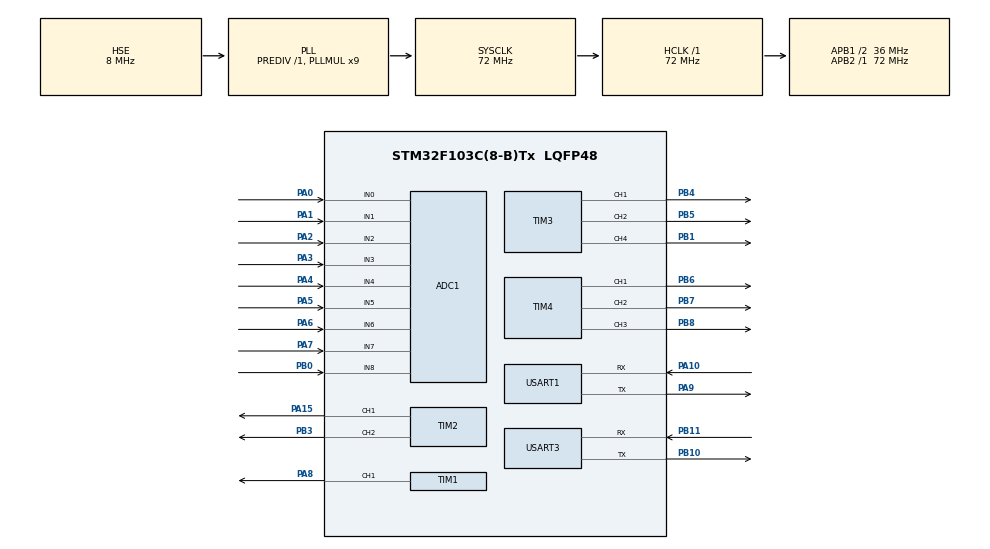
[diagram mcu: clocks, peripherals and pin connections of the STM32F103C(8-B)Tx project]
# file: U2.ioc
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ADC1.Channel-0\#ChannelRegularConversion=ADC_CHANNEL_0
ADC1.NbrOfConversionFlag=1
ADC1.Rank-0\#ChannelRegularConversion=1
ADC1.SamplingTime-0\#ChannelRegularConversion=ADC_SAMPLETIME_1CYCLE_5
ADC1.master=1
Mcu.Family=STM32F1
Mcu.Name=STM32F103C(8-B)Tx
Mcu.Package=LQFP48
NVIC.PriorityGroup=NVIC_PRIORITYGROUP_4
PA0-WKUP.Signal=ADCx_IN0
PA1.Signal=ADCx_IN1
PA10.Mode=Asynchronous
PA10.Signal=USART1_RX
PA13.Mode=Serial_Wire
PA13.Signal=SYS_JTMS-SWDIO
PA14.Mode=Serial_Wire
PA14.Signal=SYS_JTCK-SWCLK
PA15.Signal=S_TIM2_CH1_ETR
PA2.Signal=ADCx_IN2
PA3.Signal=ADCx_IN3
PA4.Signal=ADCx_IN4
PA5.Signal=ADCx_IN5
PA6.Signal=ADCx_IN6
PA7.Signal=ADCx_IN7
PA8.Signal=S_TIM1_CH1
PA9.Mode=Asynchronous
PA9.Signal=USART1_TX
PB0.Signal=ADCx_IN8
PB1.Signal=S_TIM3_CH4
PB10.Mode=Asynchronous
PB10.Signal=USART3_TX
PB11.Mode=Asynchronous
PB11.Signal=USART3_RX
PB3.Signal=S_TIM2_CH2
PB4.Signal=S_TIM3_CH1
PB5.Signal=S_TIM3_CH2
PB6.Signal=S_TIM4_CH1
PB7.Signal=S_TIM4_CH2
PB8.Signal=S_TIM4_CH3
PD0-OSC_IN.Mode=HSE-External-Oscillator
PD0-OSC_IN.Signal=RCC_OSC_IN
PD1-OSC_OUT.Mode=HSE-External-Oscillator
PD1-OSC_OUT.Signal=RCC_OSC_OUT
ProjectManager.HeapSize=0x200
ProjectManager.StackSize=0x400
ProjectManager.TargetToolchain=MDK-ARM V5
RCC.ADCPresc=RCC_ADCPCLK2_DIV6
RCC.AHBFreq_Value=72000000
RCC.APB1CLKDivider=RCC_HCLK_DIV2
RCC.APB1Freq_Value=36000000
RCC.APB1TimFreq_Value=72000000
RCC.APB2Freq_Value=72000000
RCC.APB2TimFreq_Value=72000000
RCC.HCLKFreq_Value=72000000
RCC.PLLMUL=RCC_PLL_MUL9
RCC.PLLSourceVirtual=RCC_PLLSOURCE_HSE
RCC.SYSCLKFreq_VALUE=72000000
RCC.SYSCLKSource=RCC_SYSCLKSOURCE_PLLCLK
RCC.USBFreq_Value=72000000
SH.ADCx_IN0.0=ADC1_IN0,IN0
SH.ADCx_IN1.0=ADC1_IN1,IN1
SH.ADCx_IN2.0=ADC1_IN2,IN2
SH.ADCx_IN3.0=ADC1_IN3,IN3
SH.ADCx_IN4.0=ADC1_IN4,IN4
SH.ADCx_IN5.0=ADC1_IN5,IN5
SH.ADCx_IN6.0=ADC1_IN6,IN6
SH.ADCx_IN7.0=ADC1_IN7,IN7
SH.ADCx_IN8.0=ADC1_IN8,IN8
SH.S_TIM1_CH1.0=TIM1_CH1,Output Compare1 CH1
SH.S_TIM2_CH1_ETR.0=TIM2_CH1,PWM Generation1 CH1
SH.S_TIM2_CH2.0=TIM2_CH2,PWM Generation2 CH2
SH.S_TIM3_CH1.0=TIM3_CH1,PWM Generation1 CH1
SH.S_TIM3_CH2.0=TIM3_CH2,PWM Generation2 CH2
SH.S_TIM3_CH4.0=TIM3_CH4,PWM Generation4 CH4
SH.S_TIM4_CH1.0=TIM4_CH1,PWM Generation1 CH1
SH.S_TIM4_CH2.0=TIM4_CH2,PWM Generation2 CH2
SH.S_TIM4_CH3.0=TIM4_CH3,PWM Generation3 CH3
TIM1.Channel-Output\ Compare1\ CH1=TIM_CHANNEL_1
TIM2.Channel-PWM\ Generation1\ CH1=TIM_CHANNEL_1
TIM2.Channel-PWM\ Generation2\ CH2=TIM_CHANNEL_2
TIM3.Channel-PWM\ Generation1\ CH1=TIM_CHANNEL_1
TIM3.Channel-PWM\ Generation2\ CH2=TIM_CHANNEL_2
TIM3.Channel-PWM\ Generation4\ CH4=TIM_CHANNEL_4
TIM4.Channel-PWM\ Generation1\ CH1=TIM_CHANNEL_1
TIM4.Channel-PWM\ Generation2\ CH2=TIM_CHANNEL_2
TIM4.Channel-PWM\ Generation3\ CH3=TIM_CHANNEL_3
USART1.VirtualMode=VM_ASYNC
USART3.VirtualMode=VM_ASYNC
board=custom

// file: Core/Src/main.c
/* USER CODE BEGIN Header */
/**
  ******************************************************************************
  * @file           : main.c
  * @brief          : Main program body
  ******************************************************************************
  * @attention
  *
  * Copyright (c) 2026 STMicroelectronics.
  * All rights reserved.
  *
  * This software is licensed under terms that can be found in the LICENSE file
  * in the root directory of this software component.
  * If no LICENSE file comes with this software, it is provided AS-IS.
  *
  ******************************************************************************
  */
/* USER CODE END Header */
#include "main.h"
#include "adc.h"
#include "tim.h"
#include "usart.h"
#include "gpio.h"

/* USER CODE BEGIN Includes */
#include "uart_cfg.h"
#include "u2_app.h"
#include "measure.h"
/* USER CODE END Includes */

void SystemClock_Config(void);

int main(void)
{

  /* MCU Configuration--------------------------------------------------------*/

  /* Reset of all peripherals, Initializes the Flash interface and the Systick. */
  HAL_Init();

  /* Configure the system clock */
  SystemClock_Config();

  /* Initialize all configured peripherals */
  MX_GPIO_Init();
  MX_ADC1_Init();
  MX_TIM1_Init();
  MX_TIM2_Init();
  MX_TIM3_Init();
  MX_TIM4_Init();
  MX_USART1_UART_Init();
  MX_USART3_UART_Init();
  /* USER CODE BEGIN 2 */
  /* 串口: 先把 HAL 句柄绑到端口号并打开接收中断, 再起应用层(注册链路处理函数)。
   * 顺序不能反: 反了的话 U1 早到的请求会被丢进空端口。 */
  UartCfg_Init();
  U2App_Init();
  /* 采集: ADC1 10 通道扫描 + DMA 循环（通道映射是本片自己的一套） */
  MEAS_Init();
  /* USER CODE END 2 */

  /* Infinite loop */
  while (1)
  {

    /* USER CODE BEGIN 3 */
    MEAS_Poll();          /* 采一轮就更新一次(非阻塞, DMA 回卷门控) */
    U2App_Run();          /* 链路轮询: 收请求 → 应答 (非阻塞) */
  }
  /* USER CODE END 3 */
}

void SystemClock_Config(void)
{
  RCC_OscInitTypeDef RCC_OscInitStruct = {0};
  RCC_ClkInitTypeDef RCC_ClkInitStruct = {0};
  RCC_PeriphCLKInitTypeDef PeriphClkInit = {0};

  /** Initializes the RCC Oscillators according to the specified parameters
  * in the RCC_OscInitTypeDef structure.
  */
  RCC_OscInitStruct.OscillatorType = RCC_OSCILLATORTYPE_HSE;
  RCC_OscInitStruct.HSEState = RCC_HSE_ON;
  RCC_OscInitStruct.HSEPredivValue = RCC_HSE_PREDIV_DIV1;
  RCC_OscInitStruct.HSIState = RCC_HSI_ON;
  RCC_OscInitStruct.PLL.PLLState = RCC_PLL_ON;
  RCC_OscInitStruct.PLL.PLLSource = RCC_PLLSOURCE_HSE;
  RCC_OscInitStruct.PLL.PLLMUL = RCC_PLL_MUL9;
  if (HAL_RCC_OscConfig(&RCC_OscInitStruct) != HAL_OK)
  {
    Error_Handler();
  }

  /** Initializes the CPU, AHB and APB buses clocks
  */
  RCC_ClkInitStruct.ClockType = RCC_CLOCKTYPE_HCLK|RCC_CLOCKTYPE_SYSCLK
                              |RCC_CLOCKTYPE_PCLK1|RCC_CLOCKTYPE_PCLK2;
  RCC_ClkInitStruct.SYSCLKSource = RCC_SYSCLKSOURCE_PLLCLK;
  RCC_ClkInitStruct.AHBCLKDivider = RCC_SYSCLK_DIV1;
  RCC_ClkInitStruct.APB1CLKDivider = RCC_HCLK_DIV2;
  RCC_ClkInitStruct.APB2CLKDivider = RCC_HCLK_DIV1;

  if (HAL_RCC_ClockConfig(&RCC_ClkInitStruct, FLASH_LATENCY_2) != HAL_OK)
  {
    Error_Handler();
  }
  PeriphClkInit.PeriphClockSelection = RCC_PERIPHCLK_ADC;
  PeriphClkInit.AdcClockSelection = RCC_ADCPCLK2_DIV6;
  if (HAL_RCCEx_PeriphCLKConfig(&PeriphClkInit) != HAL_OK)
  {
    Error_Handler();
  }
}

void Error_Handler(void)
{
  __disable_irq();
  while (1)
  {
  }
}
